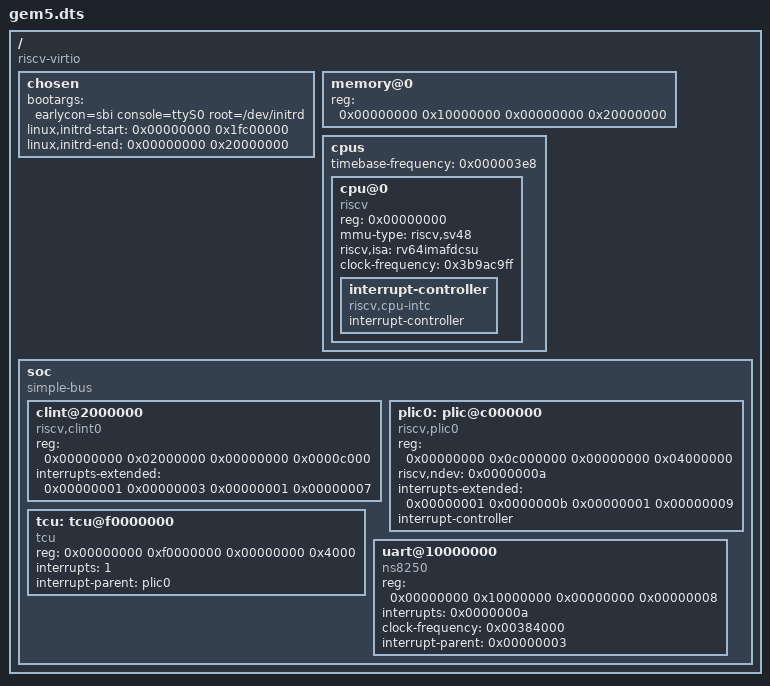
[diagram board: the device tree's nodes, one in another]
/dts-v1/;
// version:		17
// last_comp_version:	16
// boot_cpuid_phys:	0x0

/ {
    #address-cells = <0x00000002>;
    #size-cells = <0x00000002>;
    compatible = "riscv-virtio";
    chosen {
        bootargs = "earlycon=sbi console=ttyS0 root=/dev/initrd";
        linux,initrd-start = <0x00000000 0x1fc00000>;
        linux,initrd-end = <0x00000000 0x20000000>;
    };
    memory@0 {
        device_type = "memory";
        reg = <0x00000000 0x10000000 0x00000000 0x20000000>;
    };
    cpus {
        #address-cells = <0x00000001>;
        #size-cells = <0x00000000>;
        timebase-frequency = <0x000003e8>;
        cpu@0 {
            device_type = "cpu";
            reg = <0x00000000>;
            mmu-type = "riscv,sv48";
            status = "okay";
            riscv,isa = "rv64imafdcsu";
            compatible = "riscv";
            clock-frequency = <0x3b9ac9ff>;
            phandle = <0x00000002>;
            interrupt-controller {
                #interrupt-cells = <0x00000001>;
                interrupt-controller;
                compatible = "riscv,cpu-intc";
                phandle = <0x00000001>;
            };
        };
    };
    soc {
        #address-cells = <0x00000002>;
        #size-cells = <0x00000002>;
        ranges;
        compatible = "simple-bus";
        clint@2000000 {
            reg = <0x00000000 0x02000000 0x00000000 0x0000c000>;
            interrupts-extended = <0x00000001 0x00000003 0x00000001 0x00000007>;
            compatible = "riscv,clint0";
        };
        plic0: plic@c000000 {
            reg = <0x00000000 0x0c000000 0x00000000 0x04000000>;
            #address-cells = <0x00000000>;
            #interrupt-cells = <0x00000001>;
            phandle = <0x00000003>;
            riscv,ndev = <0x0000000a>;
            interrupts-extended = <0x00000001 0x0000000b 0x00000001 0x00000009>;
            interrupt-controller;
            compatible = "riscv,plic0";
        };
        tcu: tcu@f0000000 {
            reg = <0x00000000 0xf0000000 0x00000000 0x4000>;
            interrupts = <1>;
            interrupt-parent = <&plic0>;
            compatible = "tcu";
        };
        uart@10000000 {
            reg = <0x00000000 0x10000000 0x00000000 0x00000008>;
            interrupts = <0x0000000a>;
            clock-frequency = <0x00384000>;
            interrupt-parent = <0x00000003>;
            compatible = "ns8250", "gem5,uart0";
        };
    };
};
